# HK32L0xx register map
Vendor: HKMicroChip Ltd.; Series: HK32L0xx; File version: 1.3
CPU: CM0 r0p0, little endian, no MPU, no FPU, 3 interrupt priority bits
Registers are 32-bit, read-write, reset 0x0 unless marked. A register's access mark holds for its fields unless they carry their own. Offsets are from the block's base; [hi:lo] are bit positions.

## TIM16
Base 0x40014400
Same registers: TIM17 0x40014800
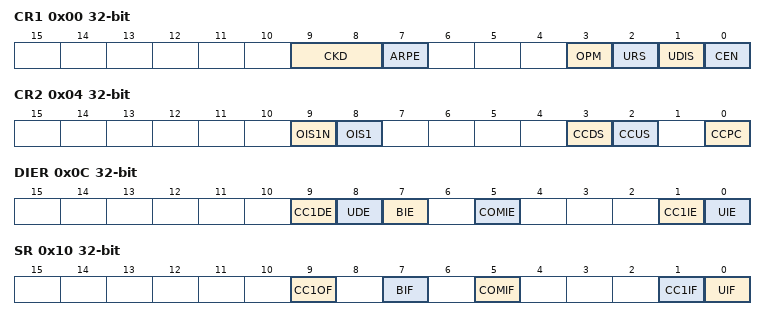
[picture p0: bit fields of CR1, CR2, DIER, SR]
0x00 CR1
  [9:8] CKD — Clock division
  [7] ARPE — Auto-reload preload enable
  [3] OPM — One pulse mode
  [2] URS — Update request source
  [1] UDIS — Update disable
  [0] CEN — Counter enable
0x04 CR2
  [9] OIS1N — Output Idle state 1
  [8] OIS1 — Output Idle state 1
  [3] CCDS — Capture/Compare DMA selection
  [2] CCUS — Capture/Compare control update selection
  [0] CCPC — Capture/Compare preloaded control
0x0C DIER
  [9] CC1DE — Capture/Compare 1 DMA request enable
  [8] UDE — Update DMA request enable
  [7] BIE — Break interrupt enable
  [5] COMIE — COM interrupt enable
  [1] CC1IE — Capture/Compare 1 interrupt enable
  [0] UIE — Update interrupt enable
0x10 SR
  [9] CC1OF — Capture/Compare 1 overcapture flag
  [7] BIF — Break interrupt flag
  [5] COMIF — COM interrupt flag
  [1] CC1IF — Capture/Compare 1 interrupt flag
  [0] UIF — Update interrupt flag
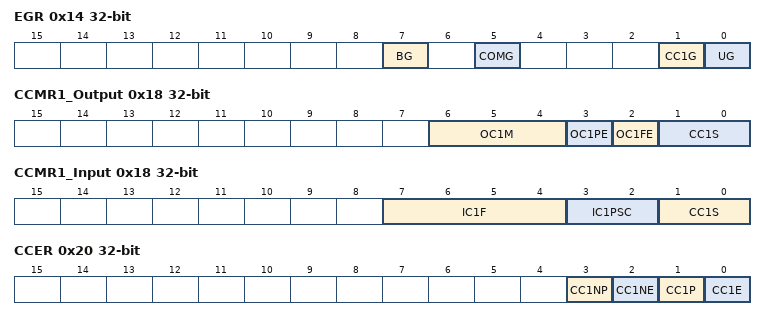
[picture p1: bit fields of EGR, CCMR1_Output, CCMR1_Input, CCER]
0x14 EGR wo
  [7] BG — Break generation
  [5] COMG — Capture/Compare control update generation
  [1] CC1G — Capture/Compare 1 generation
  [0] UG — Update generation
0x18 CCMR1_Output
  [6:4] OC1M — Output Compare 1 mode
  [3] OC1PE — Output Compare 1 preload enable
  [2] OC1FE — Output Compare 1 fast enable
  [1:0] CC1S — Capture/Compare 1 selection
0x18 CCMR1_Input (alternate view of CCMR1_Output)
  [7:4] IC1F — Input capture 1 filter
  [3:2] IC1PSC — Input capture 1 prescaler
  [1:0] CC1S — Capture/Compare 1 Selection
0x20 CCER
  [3] CC1NP — Capture/Compare 1 complementary output polarity
  [2] CC1NE — Capture/Compare 1 complementary output enable
  [1] CC1P — Capture/Compare 1 output polarity
  [0] CC1E — Capture/Compare 1 output enable
0x24 CNT
  [15:0] CNT — Counter value
0x28 PSC
  [15:0] PSC — Prescaler value
0x2C ARR reset 0xFFFF
  [15:0] ARR — Auto-reload value
0x30 RCR
  [7:0] REP — Repetition counter value
0x34 CCR1
  [15:0] CCR1 — Capture/Compare 1 value
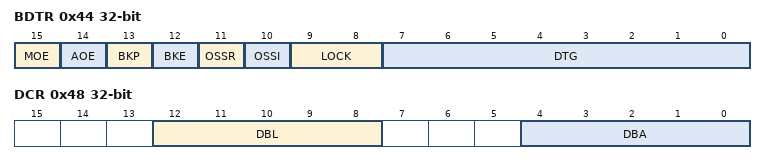
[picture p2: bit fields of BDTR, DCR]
0x44 BDTR
  [15] MOE — Main output enable
  [14] AOE — Automatic output enable
  [13] BKP — Break polarity
  [12] BKE — Break enable
  [11] OSSR — Off-state selection for Run mode
  [10] OSSI — Off-state selection for Idle mode
  [9:8] LOCK — Lock configuration
  [7:0] DTG — Dead-time generator setup
0x48 DCR
  [12:8] DBL — DMA burst length
  [4:0] DBA — DMA base address
0x4C DMAR
  [15:0] DMAB — DMA register for burst accesses

## LPTIM1
Base 0x40007C00
Same registers: LPTIM2 0x40009400, LPTIM3 0x40014C00
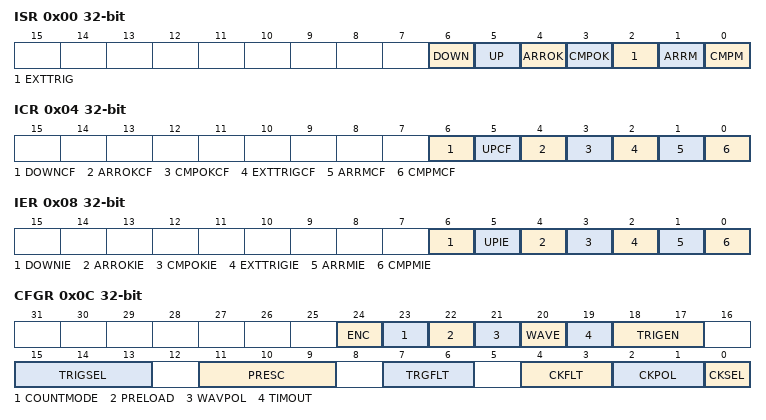
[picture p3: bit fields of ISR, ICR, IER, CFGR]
0x00 ISR ro
  [6] DOWN — Counter direction change up to down
  [5] UP — Counter direction change down to up
  [4] ARROK — Auto reload register is written done
  [3] CMPOK — Compare register is written done
  [2] EXTTRIG — External trigger event
  [1] ARRM — Auto reload
  [0] CMPM — Compare match
0x04 ICR wo
  [6] DOWNCF — DOWN clear flag
  [5] UPCF — UP clear flag
  [4] ARROKCF — ARROK clear flag
  [3] CMPOKCF — CMPOK clear flag
  [2] EXTTRIGCF — EXTTRIG clear flag
  [1] ARRMCF — ARRM clear flag
  [0] CMPMCF — CMPM clear flag
0x08 IER
  [6] DOWNIE — DOWN interrupt enable
  [5] UPIE — UP interrupt enable
  [4] ARROKIE — ARROK interrupt enable
  [3] CMPOKIE — CMPOK interrupt enable
  [2] EXTTRIGIE — EXTTRIG interrupt enable
  [1] ARRMIE — ARRM interrupt enable
  [0] CMPMIE — CMPM interrupt enable
0x0C CFGR
  [24] ENC — Counter mode enable
  [23] COUNTMODE — Counter mode enable
  [22] PRELOAD — Register update mode
  [21] WAVPOL — Wave polarity
  [20] WAVE — Wave shape
  [19] TIMOUT — Enable timeout
  [18:17] TRIGEN — Trigger enable
  [15:13] TRIGSEL — Trigger seletion
  [11:9] PRESC — Clock prescaler
  [7:6] TRGFLT — Digital filter for trigger
  [4:3] CKFLT — Digital filter for external clock
  [2:1] CKPOL — Clock polarity
  [0] CKSEL — Clock source selection
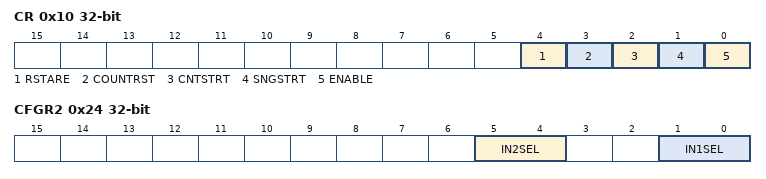
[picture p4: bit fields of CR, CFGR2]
0x10 CR
  [4] RSTARE — Reset the LPTIM_CNT register by reading
  [3] COUNTRST — Counter reset
  [2] CNTSTRT — Counter starts in consecutive mode
  [1] SNGSTRT — Counter starts in single mode
  [0] ENABLE — LPTIM enable
0x14 CMP
  [15:0] CMP — Compare value
0x18 ARR reset 0x1
  [15:0] ARR — Auto reload value
0x1C CNT
  [15:0] CNT — Counter value
0x24 CFGR2
  [5:4] IN2SEL — LPTIM input2 selection
  [1:0] IN1SEL — LPTIM input1 selection
